# RS14100 register map
File version: 1.0
CPU: CM4 r0p1, little endian, MPU, FPU, 4 interrupt priority bits
Registers are 32-bit, read-write, reset 0x0 unless marked. A register's access mark holds for its fields unless they carry their own. Offsets are from the block's base; [hi:lo] are bit positions; 'fields as' and 'values as' point back to an identical list.

## ULTRA_LOW_POWER_DOMAINS — This is explain the Ultra low power domains peripherals registers.
Base 0x24048000
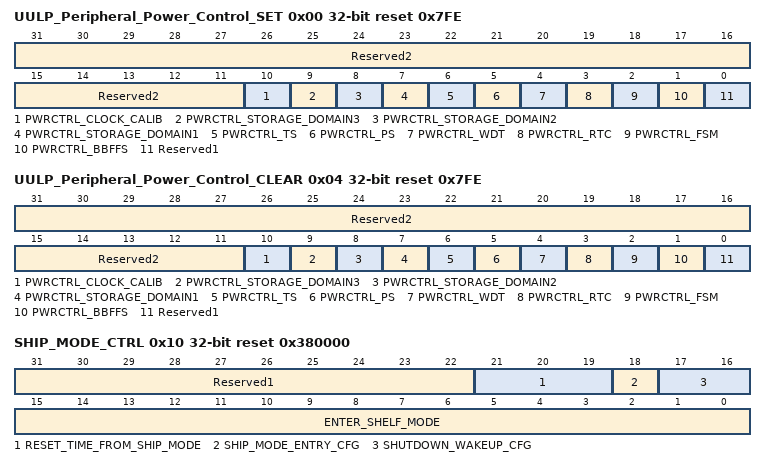
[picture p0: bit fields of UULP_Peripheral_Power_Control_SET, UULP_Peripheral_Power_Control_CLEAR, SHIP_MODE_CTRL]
0x00 UULP_Peripheral_Power_Control_SET reset 0x7FE — Enables power for UULP-PERIPHERALS domains
  [31:11] Reserved2 — It is recommended to write these bits to 0.
  [10] PWRCTRL_CLOCK_CALIB — Writing 1 to this enables power to the CLOCK-CALIB.
    0=Disable (Writing 0 to this has no effect.); 1=Enable (Writing 1 to this enables power to the CLOCK-CALIB.)
  [9] PWRCTRL_STORAGE_DOMAIN3 — Writing 1 to this enables power to the STORAGE-DOMAIN3.
    0=Disable (Writing 0 to this has no effect.); 1=Enable (Writing 1 to this enables power to the STORAGE-DOMAIN3.)
  [8] PWRCTRL_STORAGE_DOMAIN2 — Writing 1 to this enables power to the STORAGE-DOMAIN2.
    0=Disable (Writing 0 to this has no effect.); 1=Enable (Writing 1 to this enables power to the STORAGE-DOMAIN2.)
  [7] PWRCTRL_STORAGE_DOMAIN1 — Writing 1 to this enables power to the STORAGE-DOMAIN1.
    0=Disable (Writing 0 to this has no effect.); 1=Enable (Writing 1 to this enables power to the STORAGE-DOMAIN1.)
  [6] PWRCTRL_TS — Writing 1 to this enables power to the TS.
    0=Disable (Writing 0 to this has no effect.); 1=Enable (Writing 1 to this enables power to the PS.)
  [5] PWRCTRL_PS — It is enable power control to PS.
    values as PWRCTRL_TS
  [4] PWRCTRL_WDT — It is enable power control to WDT.
    0=Disable (Writing 0 to this has no effect.); 1=Enable (Writing 1 to this enables power to the WDT.)
  [3] PWRCTRL_RTC — It is enable power control to RTC.
    0=Disable (Writing 0 to this has no effect.); 1=Enable (Writing 1 to this enables power to the RTC.)
  [2] PWRCTRL_FSM — It is enable power control to FSM.
    0=Disable (Writing 0 to this has no effect.); 1=Enable (Writing 1 to this enables power to the FSM.)
  [1] PWRCTRL_BBFFS — It is enable power control to BBFFS.
    0=Disable (Writing 0 to this has no effect.); 1=Enable (Writing 1 to this enables power to the BBFFS.)
  [0] Reserved1 — It is recommended to write these bits to 0.
0x04 UULP_Peripheral_Power_Control_CLEAR reset 0x7FE — Disables power for UULP-PERIPHERALS domains
  [31:11] Reserved2 — It is recommended to write these bits to 0.
  [10] PWRCTRL_CLOCK_CALIB — It is disable power control to the CLOCK-CALIB.
    values as UULP_Peripheral_Power_Control_SET.PWRCTRL_CLOCK_CALIB
  [9] PWRCTRL_STORAGE_DOMAIN3 — It is disable power control to the STORAGE-DOMAIN3.
    values as UULP_Peripheral_Power_Control_SET.PWRCTRL_STORAGE_DOMAIN3
  [8] PWRCTRL_STORAGE_DOMAIN2 — It is disable power control to the STORAGE-DOMAIN2.
    values as UULP_Peripheral_Power_Control_SET.PWRCTRL_STORAGE_DOMAIN2
  [7] PWRCTRL_STORAGE_DOMAIN1 — It is disable power control to STORAGE-DOMAIN1.
    0=Disable (Writing 0 to this has no effect.); 1=Enable (Writing 1 to this disables power to the STORAGE-DOMAIN1.)
  [6] PWRCTRL_TS — It is disable power control to TS.
    0=Disable (Writing 0 to this has no effect.); 1=Enable (Writing 1 to this disables power to the PS.)
  [5] PWRCTRL_PS — It is disable power control to PS.
    values as PWRCTRL_TS
  [4] PWRCTRL_WDT — It is disable power control to WDT.
    0=Disable (Writing 0 to this has no effect.); 1=Enable (Writing 1 to this disables power to the WDT.)
  [3] PWRCTRL_RTC — It is disable power control to RTC.
    0=Disable (Writing 0 to this has no effect.); 1=Enable (Writing 1 to this disables power to the RTC.)
  [2] PWRCTRL_FSM — It is disable power control to FSM.
    0=Disable (Writing 0 to this has no effect.); 1=Enable (Writing 1 to this disables power to the FSM.)
  [1] PWRCTRL_BBFFS — It is disable power control to BBFFS.
    0=Disable (Writing 0 to this has no effect.); 1=Enable (Writing 1 to this disables power to the BBFFS.)
  [0] Reserved1 — It is recommended to write these bits to 0.
0x10 SHIP_MODE_CTRL reset 0x380000 — SHIP Mode Entry/Exit Configuration Register.
  [31:22] Reserved1 — It is recommended to write these bits to 0.
  [21:19] RESET_TIME_FROM_SHIP_MODE — Configures the Reset time in number of clocks @32KHz RC Clock during exit from SHIP mode.
  [18] SHIP_MODE_ENTRY_CFG — Configures the Trigger for entering SHIP mode.Writing 1 to this enable entry to SHIP mode on Falling edge on the UULP Vbat GPIO configuration as mentioned in SHUTDOWN_WAKEUP_CFG.
  [17:16] SHUTDOWN_WAKEUP_CFG — Enables the Wakeup trigger from SHIP mode based on rising edge of the below combinations.
    0=UULP Vbat GPIO2; 1=UULP Vbat GPIO3; 2=UULP Vbat GPIO2 and GPIO3; 3=UULP Vbat GPIO2 OR GPIO3
  [15:0] ENTER_SHELF_MODE wo — Writing 0xAAAA to this provides immediate trigger to SHIP mode.
